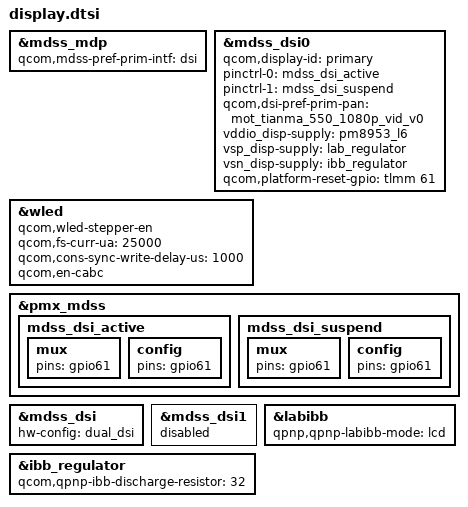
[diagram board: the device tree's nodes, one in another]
#include "dsi-panel/dsi-panel-mot-dummy-qhd-video.dtsi"
#include "dsi-panel/dsi-panel-mot-tianma-550-1080p-vid.dtsi"
#include "dsi-panel/dsi-panel-mot-djn-550-1080p-vid.dtsi"

&mdss_mdp {
	qcom,mdss-pref-prim-intf = "dsi";
};

&mdss_dsi0 {
	qcom,display-id = "primary";
};

&wled {
	qcom,wled-stepper-en;
	qcom,fs-curr-ua = <25000>;
	qcom,cons-sync-write-delay-us = <1000>;
	qcom,en-cabc;
};

&pmx_mdss {
	mdss_dsi_active {
		mux {
			pins = "gpio61";
		};

		config {
			pins = "gpio61";
		};
	};

	mdss_dsi_suspend {
		mux {
			pins = "gpio61";
		};

		config {
			pins = "gpio61";
		};
	};
};

&mdss_dsi {
	hw-config = "dual_dsi";
};

&mdss_dsi0 {
	pinctrl-names = "mdss_default", "mdss_sleep";
	pinctrl-0 = <&mdss_dsi_active >;
	pinctrl-1 = <&mdss_dsi_suspend>;

	qcom,dsi-pref-prim-pan = <&mot_tianma_550_1080p_vid_v0>;

	/delete-property/ vdd-supply;
	vddio_disp-supply = <&pm8953_l6>;
	vsp_disp-supply = <&lab_regulator>;
	vsn_disp-supply = <&ibb_regulator>;

	qcom,platform-reset-gpio = <&tlmm 61 0>;
};

&mdss_dsi1 {
	status = "disabled";
};

/* display boost and inverting boost regulators */
&labibb {
	status = "ok";
	qpnp,qpnp-labibb-mode = "lcd";
};

&ibb_regulator {
	qcom,qpnp-ibb-discharge-resistor = <32>;
};
